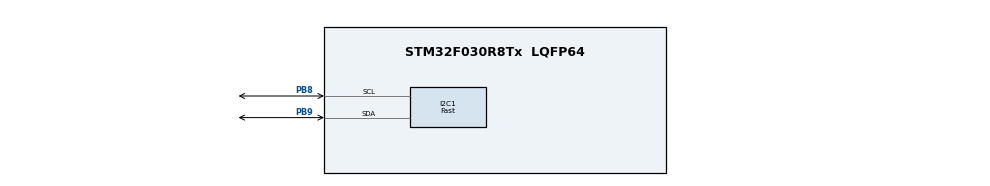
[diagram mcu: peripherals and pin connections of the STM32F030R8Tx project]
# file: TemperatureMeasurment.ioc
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I2C1.I2C_Speed_Mode=I2C_Fast
I2C1.Timing=0x0000020B
Mcu.Family=STM32F0
Mcu.Name=STM32F030R8Tx
Mcu.Package=LQFP64
NVIC.I2C1_IRQn=true\:0\:0\:false\:false\:true\:true\:true\:true
NVIC.TIM3_IRQn=true\:0\:0\:false\:false\:true\:true\:true\:true
PA13.Mode=Serial_Wire
PA13.Signal=SYS_SWDIO
PA14.Mode=Serial_Wire
PA14.Signal=SYS_SWCLK
PB8.Mode=I2C
PB8.Signal=I2C1_SCL
PB9.Mode=I2C
PB9.Signal=I2C1_SDA
ProjectManager.HeapSize=0x200
ProjectManager.StackSize=0x400
ProjectManager.TargetToolchain=STM32CubeIDE
TIM3.Period=1000-1
TIM3.Prescaler=800-1
VP_TIM3_VS_ClockSourceINT.Mode=Internal
board=custom

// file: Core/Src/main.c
/* USER CODE BEGIN Header */
/**
  ******************************************************************************
  * @file           : main.c
  * @brief          : Main program body
  ******************************************************************************
  * @attention
  *
  * Copyright (c) 2022 STMicroelectronics.
  * All rights reserved.
  *
  * This software is licensed under terms that can be found in the LICENSE file
  * in the root directory of this software component.
  * If no LICENSE file comes with this software, it is provided AS-IS.
  *
  ******************************************************************************
  */
/* USER CODE END Header */
#include "main.h"

/* USER CODE BEGIN Includes */
#include "ssd1306.h"
#include "fonts.h"

/* USER CODE END Includes */

I2C_HandleTypeDef hi2c1;

TIM_HandleTypeDef htim3;

/* USER CODE BEGIN PV */

/* Variables For AHT10*/

uint8_t AHT10_RX_Data[6];
uint32_t AHT10_ADC_Raw;
float AHT10_Temperature;
float AHT10_Humidity;
char TempText[4];
char Title[10];

#define AHT10_ADRESS (0x38<<1)

uint8_t AHT10_InitComand=0xE1;
uint8_t AHT10_SoftResetComand=0xBA;

uint8_t AHT10_TmpHumdComand=0xAC;

//uint8_t AHT10_TmpHumdComand[3]={0xAC,0X33,0X00};

/*Aditional Variables*/
uint8_t AHT10_Switcher=255;
uint8_t T_100ms=255;
uint8_t SendToLCD=0;

/* USER CODE END PV */

void SystemClock_Config(void);
static void MX_GPIO_Init(void);
static void MX_I2C1_Init(void);
static void MX_TIM3_Init(void);

/* USER CODE BEGIN 0 */

void  HAL_TIM_PeriodElapsedCallback(TIM_HandleTypeDef *htim)
{
	if (htim->Instance==TIM3) {
		T_100ms=255;
	}
}

/* USER CODE END 0 */

int main(void)
{

  /* MCU Configuration--------------------------------------------------------*/

  /* Reset of all peripherals, Initializes the Flash interface and the Systick. */
  HAL_Init();

  /* Configure the system clock */
  SystemClock_Config();

  /* Initialize all configured peripherals */
  MX_GPIO_Init();
  MX_I2C1_Init();
  MX_TIM3_Init();
  /* USER CODE BEGIN 2 */
  HAL_TIM_Base_Start_IT(&htim3);

  SSD1306_Init (); // initialize the display

 HAL_I2C_Master_Transmit(&hi2c1, AHT10_ADRESS, &AHT10_InitComand,1,1000);
 HAL_Delay(100);
 HAL_I2C_Master_Transmit(&hi2c1, AHT10_ADRESS, &AHT10_SoftResetComand,1,1000);
 HAL_Delay(100);

  /* USER CODE END 2 */

  /* Infinite loop */
  /* USER CODE BEGIN WHILE */
  while (1)
  {

	  if (T_100ms) {
		if (AHT10_Switcher)
		{
			HAL_I2C_Master_Transmit_IT(&hi2c1, AHT10_ADRESS, &AHT10_TmpHumdComand,1);
		}
		else
		{

			HAL_I2C_Master_Receive_IT(&hi2c1, AHT10_ADRESS, (uint8_t*)AHT10_RX_Data, 6);

			if (~AHT10_RX_Data[0]& 0X80)
			{
				/* Convert to Temperature in °C */
				AHT10_ADC_Raw = (((uint32_t)AHT10_RX_Data[3] & 15) << 16) | ((uint32_t)AHT10_RX_Data[4] << 8) | AHT10_RX_Data[5];
				AHT10_Temperature = (float)(AHT10_ADC_Raw * 200.00 / 1048576.00) - 50.00;
				/* Convert to Relative Humidity in % */
				AHT10_ADC_Raw = ((uint32_t)AHT10_RX_Data[1] << 12) | ((uint32_t)AHT10_RX_Data[2] << 4) | (AHT10_RX_Data[3] >> 4);
				AHT10_Humidity = (float)(AHT10_ADC_Raw*100.00/1048576.00);
				SendToLCD=1;
			}

		}

		AHT10_Switcher = ~AHT10_Switcher; /* Invert */
		T_100ms = 0; /* Nulify */
	  }

if (SendToLCD==1) {

	sprintf(Title,"Temp:");

	SSD1306_GotoXY (0,0); // goto 10, 10
	SSD1306_Puts ((char*)Title, &Font_7x10, 1);

	sprintf(TempText,"%d.%01u", (int) AHT10_Temperature, (int) ((AHT10_Temperature - (int) AHT10_Temperature ) * 100) );
	SSD1306_GotoXY (10,10); // goto 10, 10
	SSD1306_Puts ((char*)TempText, &Font_11x18, 1);

	sprintf(Title,"Hum:");

	SSD1306_GotoXY (0,30); // goto 10, 10
	SSD1306_Puts ((char*)Title, &Font_7x10, 1);

	sprintf(TempText,"%d.%01u", (int) AHT10_Humidity, (int) ((AHT10_Humidity - (int) AHT10_Humidity ) * 100) );
	SSD1306_GotoXY (10, 40);
	SSD1306_Puts ((char*)TempText, &Font_11x18, 1);
	SSD1306_UpdateScreen(); // update screen

	HAL_Delay(1000);
	SendToLCD=0;
}

    /* USER CODE END WHILE */

  }
}

void SystemClock_Config(void)
{
  RCC_OscInitTypeDef RCC_OscInitStruct = {0};
  RCC_ClkInitTypeDef RCC_ClkInitStruct = {0};
  RCC_PeriphCLKInitTypeDef PeriphClkInit = {0};

  /** Initializes the RCC Oscillators according to the specified parameters
  * in the RCC_OscInitTypeDef structure.
  */
  RCC_OscInitStruct.OscillatorType = RCC_OSCILLATORTYPE_HSI;
  RCC_OscInitStruct.HSIState = RCC_HSI_ON;
  RCC_OscInitStruct.HSICalibrationValue = RCC_HSICALIBRATION_DEFAULT;
  RCC_OscInitStruct.PLL.PLLState = RCC_PLL_NONE;
  if (HAL_RCC_OscConfig(&RCC_OscInitStruct) != HAL_OK)
  {
    Error_Handler();
  }

  /** Initializes the CPU, AHB and APB buses clocks
  */
  RCC_ClkInitStruct.ClockType = RCC_CLOCKTYPE_HCLK|RCC_CLOCKTYPE_SYSCLK
                              |RCC_CLOCKTYPE_PCLK1;
  RCC_ClkInitStruct.SYSCLKSource = RCC_SYSCLKSOURCE_HSI;
  RCC_ClkInitStruct.AHBCLKDivider = RCC_SYSCLK_DIV1;
  RCC_ClkInitStruct.APB1CLKDivider = RCC_HCLK_DIV1;

  if (HAL_RCC_ClockConfig(&RCC_ClkInitStruct, FLASH_LATENCY_0) != HAL_OK)
  {
    Error_Handler();
  }
  PeriphClkInit.PeriphClockSelection = RCC_PERIPHCLK_I2C1;
  PeriphClkInit.I2c1ClockSelection = RCC_I2C1CLKSOURCE_HSI;
  if (HAL_RCCEx_PeriphCLKConfig(&PeriphClkInit) != HAL_OK)
  {
    Error_Handler();
  }
}

static void MX_I2C1_Init(void)
{

  hi2c1.Instance = I2C1;
  hi2c1.Init.Timing = 0x0000020B;
  hi2c1.Init.OwnAddress1 = 0;
  hi2c1.Init.AddressingMode = I2C_ADDRESSINGMODE_7BIT;
  hi2c1.Init.DualAddressMode = I2C_DUALADDRESS_DISABLE;
  hi2c1.Init.OwnAddress2 = 0;
  hi2c1.Init.OwnAddress2Masks = I2C_OA2_NOMASK;
  hi2c1.Init.GeneralCallMode = I2C_GENERALCALL_DISABLE;
  hi2c1.Init.NoStretchMode = I2C_NOSTRETCH_DISABLE;
  if (HAL_I2C_Init(&hi2c1) != HAL_OK)
  {
    Error_Handler();
  }

  /** Configure Analogue filter
  */
  if (HAL_I2CEx_ConfigAnalogFilter(&hi2c1, I2C_ANALOGFILTER_ENABLE) != HAL_OK)
  {
    Error_Handler();
  }

  /** Configure Digital filter
  */
  if (HAL_I2CEx_ConfigDigitalFilter(&hi2c1, 0) != HAL_OK)
  {
    Error_Handler();
  }

}

static void MX_TIM3_Init(void)
{

  TIM_ClockConfigTypeDef sClockSourceConfig = {0};
  TIM_MasterConfigTypeDef sMasterConfig = {0};

  htim3.Instance = TIM3;
  htim3.Init.Prescaler = 800-1;
  htim3.Init.CounterMode = TIM_COUNTERMODE_UP;
  htim3.Init.Period = 1000-1;
  htim3.Init.ClockDivision = TIM_CLOCKDIVISION_DIV1;
  htim3.Init.AutoReloadPreload = TIM_AUTORELOAD_PRELOAD_DISABLE;
  if (HAL_TIM_Base_Init(&htim3) != HAL_OK)
  {
    Error_Handler();
  }
  sClockSourceConfig.ClockSource = TIM_CLOCKSOURCE_INTERNAL;
  if (HAL_TIM_ConfigClockSource(&htim3, &sClockSourceConfig) != HAL_OK)
  {
    Error_Handler();
  }
  sMasterConfig.MasterOutputTrigger = TIM_TRGO_RESET;
  sMasterConfig.MasterSlaveMode = TIM_MASTERSLAVEMODE_DISABLE;
  if (HAL_TIMEx_MasterConfigSynchronization(&htim3, &sMasterConfig) != HAL_OK)
  {
    Error_Handler();
  }

}

static void MX_GPIO_Init(void)
{

  /* GPIO Ports Clock Enable */
  __HAL_RCC_GPIOA_CLK_ENABLE();
  __HAL_RCC_GPIOB_CLK_ENABLE();

}

void Error_Handler(void)
{
  __disable_irq();
  while (1)
  {
  }
}
